# EFR32MG24B110F1536GM48 register map
Vendor: Silicon Labs; Series: EFR32; File version: B
Registers are 32-bit, read-write, reset 0x0 unless marked. A register's access mark holds for its fields unless they carry their own. Offsets are from the block's base; [hi:lo] are bit positions; {n}, {i} and the like mark numbered series.

## HFRCO0_NS — HFRCO0_NS Registers
Base 0x50010000
Same registers: HFRCO0_S 0x40010000, HFRCOEM23_S 0x4A000000, HFRCOEM23_NS 0x5A000000
0x00 IPVERSION ro reset 0x2
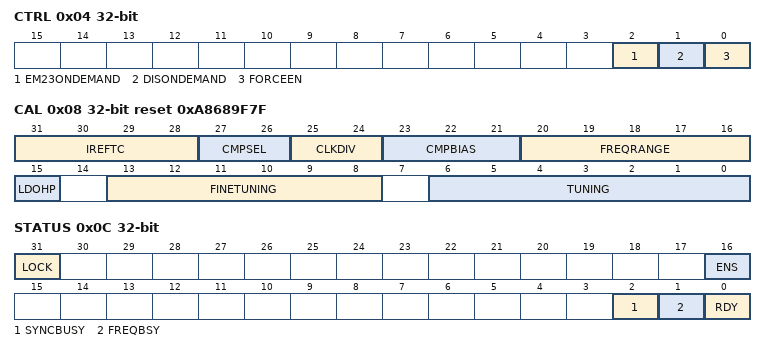
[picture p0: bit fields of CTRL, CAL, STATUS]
0x04 CTRL
  [2] EM23ONDEMAND
  [1] DISONDEMAND — Disable On-demand
  [0] FORCEEN — Force Enable
0x08 CAL reset 0xA8689F7F
  [31:28] IREFTC — Tempco Trim on Comparator Current
  [27:26] CMPSEL — Comparator Load Select
  [25:24] CLKDIV — Locally Divide HFRCO Clock Output
    0=DIV1 (Divide by 1.); 1=DIV2 (Divide by 2.); 2=DIV4 (Divide by 4.)
  [23:21] CMPBIAS — Comparator Bias Current
  [20:16] FREQRANGE — Frequency Range
  [15] LDOHP — LDO High Power Mode
  [13:8] FINETUNING — Fine Tuning Value
  [6:0] TUNING — Tuning Value
0x0C STATUS ro
  [31] LOCK — Lock Status
    0=UNLOCKED (HFRCO is unlocked); 1=LOCKED (HFRCO is locked)
  [16] ENS — Enable Status
  [2] SYNCBUSY — Synchronization Busy
  [1] FREQBSY — Frequency Updating Busy
  [0] RDY — Ready
0x10 IF
  [0] RDY — Ready Interrupt Flag
0x14 IEN
  [0] RDY — RDY Interrupt Enable
0x1C LOCK wo reset 0x8195
  [15:0] LOCKKEY
    0x8195=UNLOCK (Unlock code)

## HOSTMAILBOX_NS — HOSTMAILBOX_NS Registers
Base 0x50098000
Same registers: HOSTMAILBOX_S 0x40098000
{0x0+4i} MSGPTR{i} (i=0..3)
  [31:0] PTR — Pointer
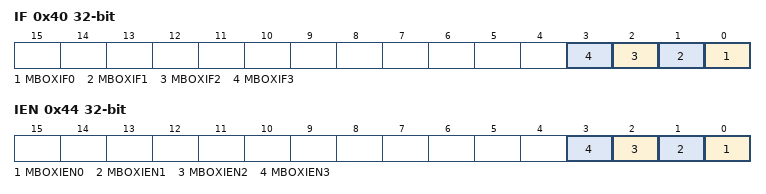
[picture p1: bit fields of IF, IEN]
0x40 IF
  [n] MBOXIF{n} (n=0..3) — Mailbox Interupt Flag
0x44 IEN
  [n] MBOXIEN{n} (n=0..3) — Mailbox Interrupt Enable

## ICACHE0_NS — ICACHE0_NS Registers
Base 0x50034000
Same registers: ICACHE0_S 0x40034000
0x00 IPVERSION ro — The read only IPVERSION field gives the version for this module. There may be minor software changes required for modules with different values of IPVERSION.
  [31:0] IPVERSION — IP version ID
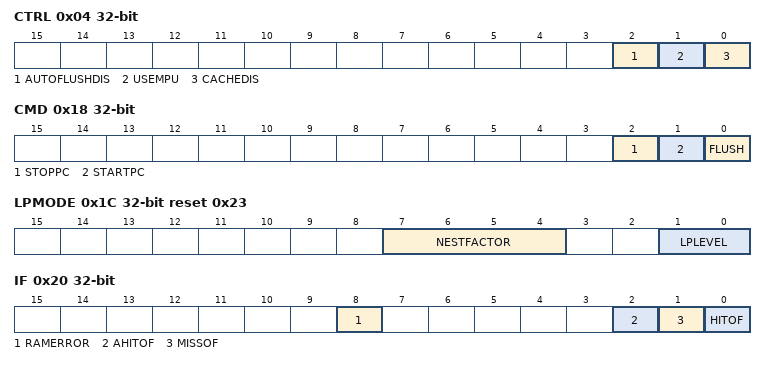
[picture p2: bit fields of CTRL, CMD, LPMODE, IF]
0x04 CTRL
  [2] AUTOFLUSHDIS — Automatic Flushing Disable
  [1] USEMPU
  [0] CACHEDIS — Cache Disable
0x08 PCHITS ro
  [31:0] PCHITS — Performance Counter Hits
0x0C PCMISSES ro
  [31:0] PCMISSES — Performance Counter Misses
0x10 PCAHITS ro
  [31:0] PCAHITS — Performance Counter Advanced Hits
0x14 STATUS ro
  [0] PCRUNNING
0x18 CMD wo
  [2] STOPPC — Stop Performance Counters
  [1] STARTPC — Start Performance Counters
  [0] FLUSH
0x1C LPMODE reset 0x23
  [7:4] NESTFACTOR — Low Power Nest Factor
  [1:0] LPLEVEL — Low Power Level
    0=BASIC (Base instruction cache functionality); 1=ADVANCED (Advanced buffering mode, where the cache uses the fetch pattern to predict highly accessed data and store it in low-energy memory); 3=MINACTIVITY (Minimum activity mode, which allows the cache to minimize activity in logic that it predicts has a low probability being used. This mode can introduce wait-states into the instruction fetch stream when the cache exits one of its low-activity states. The number of wait-states introduced is small, but users running with 0-wait-state memory and wishing to reduce the variability that the cache might introduce with additional wait-states may wish to lower the cache low-power level. Note, this mode includes the advanced buffering mode functionality.)
0x20 IF
  [8] RAMERROR — RAM error Interrupt Flag
  [2] AHITOF — Advanced Hit Overflow Interrupt Flag
  [1] MISSOF — Miss Overflow Interrupt Flag
  [0] HITOF — Hit Overflow Interrupt Flag
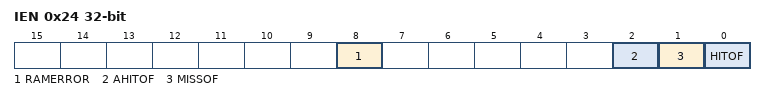
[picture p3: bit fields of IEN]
0x24 IEN
  [8] RAMERROR — RAM error Interrupt Enable
  [2] AHITOF — Advanced Hit Overflow Interrupt Enable
  [1] MISSOF — Miss Overflow Interrupt Enable
  [0] HITOF — Hit Overflow Interrupt Enable

## KEYSCAN_NS — KEYSCAN_NS Registers
Base 0x500B0000
Same registers: KEYSCAN_S 0x400B0000
0x00 IPVERSION ro reset 0x1
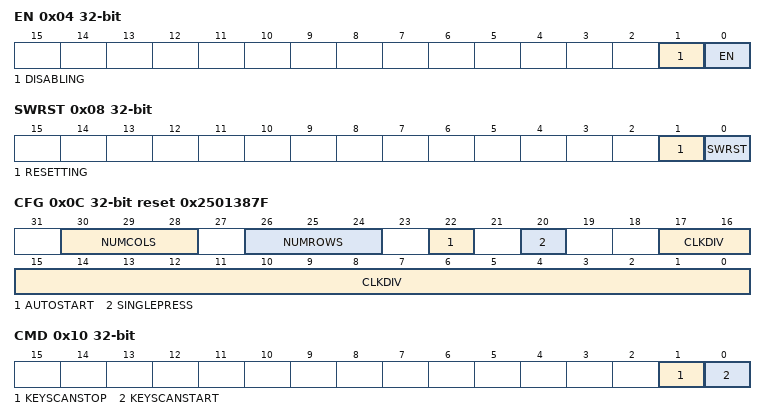
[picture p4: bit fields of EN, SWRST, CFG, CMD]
0x04 EN — Enable
  [1] DISABLING ro — Disablement busy status
  [0] EN — Enable
    0=DISABLE (Stops clocking and resets peripheral core logic.); 1=ENABLE (Enables clocking, and begins scanning if CFG.AUTOSTART is 0x1.)
0x08 SWRST — Software Reset
  [1] RESETTING ro — Software reset busy status
  [0] SWRST wo — Software reset command
0x0C CFG reset 0x2501387F — Config
  [30:28] NUMCOLS — Number of Columns
  [26:24] NUMROWS — Number of Rows
    0=RSV1 (1 Row is not supported; defaults to 3 instead); 1=RSV2 (2 Rows are not supported; defaults to 3 instead); {v}=ROW{v+1} ({v+1} Rows) (v=2..5)
  [22] AUTOSTART — Automatically Start
    0=AUTOSTARTDIS (Auto start is disabled); 1=AUTOSTARTEN (Auto start is enabled)
  [20] SINGLEPRESS
    0=MULTIPRESS (After KEYIF is set and then cleared, scanning will continue. This can give multiple interrupts for the same key press, but allow multiple key presses to be detected. To use this mode for multi-key detection, the ISR should update a section of memory of COLNUM bytes on each interrupt, until key release is detected. After key release, the section of memory where key presses are recorded can be processed.); 1=SINGLEPRESS (After KEYIF has been set and cleared, it will not set again until no key press is detected. This allows faster response since the ISR can start processing data as soon as the KEYIF is set.)
  [17:0] CLKDIV — Clock Divider
0x10 CMD wo — Command
  [1] KEYSCANSTOP, [0] KEYSCANSTART
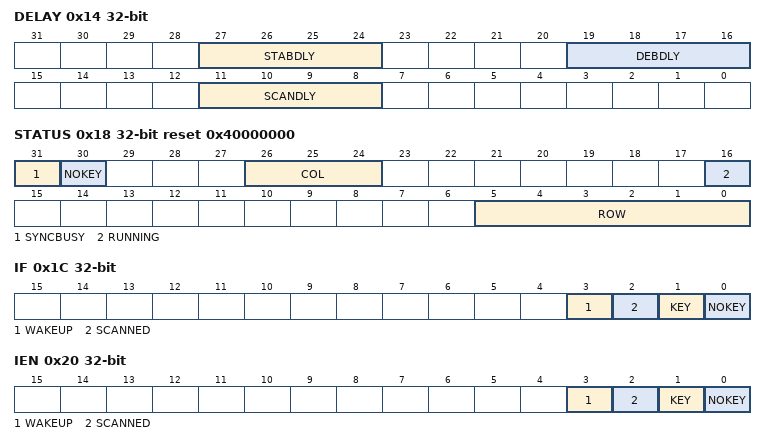
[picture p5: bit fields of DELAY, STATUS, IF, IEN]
0x14 DELAY
  [27:24] STABDLY — Row stable Delay
    0=2ms Row Stable Delay; 1=4ms Row Stable Delay; 2=6ms Row Stable Delay; 3=8ms Row Stable Delay; 4=10ms Row Stable Delay; 5=12ms Row Stable Delay; 6=14ms Row Stable Delay; 7=16ms Row Stable Delay; 8=18ms Row Stable Delay; 9=20ms Row Stable Delay; 10=22ms Row Stable Delay; 11=24ms Row Stable Delay; 12=26ms Row Stable Delay; 13=28ms Row Stable Delay; 14=30ms Row Stable Delay; 15=32ms Row Stable Delay
  [19:16] DEBDLY — Debounce Delay
    0=2ms Debounce Delay; 1=4ms Debounce Delay; 2=6ms Debounce Delay; 3=8ms Debounce Delay; 4=10ms Debounce Delay; 5=12ms Debounce Delay; 6=14ms Debounce Delay; 7=16ms Debounce Delay; 8=18ms Debounce Delay; 9=20ms Debounce Delay; 10=22ms Debounce Delay; 11=24ms Debounce Delay; 12=26ms Debounce Delay; 13=28ms Debounce Delay; 14=30ms Debounce Delay; 15=32ms Debounce Delay
  [11:8] SCANDLY — Scan Delay
    0=2ms Scan Delay; 1=4ms Scan Delay; 2=6ms Scan Delay; 3=8ms Scan Delay; 4=10ms Scan Delay; 5=12ms Scan Delay; 6=14ms Scan Delay; 7=16ms Scan Delay; 8=18ms Scan Delay; 9=20ms Scan Delay; 10=22ms Scan Delay; 11=24ms Scan Delay; 12=26ms Scan Delay; 13=28ms Scan Delay; 14=30ms Scan Delay; 15=32ms Scan Delay
0x18 STATUS ro reset 0x40000000
  [31] SYNCBUSY
  [30] NOKEY — No Key pressed status
  [26:24] COL — Column Latched
  [16] RUNNING
  [5:0] ROW — Row detection
0x1C IF — Interrupt Flags
  [3] WAKEUP
  [2] SCANNED — Completed scan
  [1] KEY — A key was pressed
  [0] NOKEY — No key was pressed
0x20 IEN — Interrupt Enables
  [3] WAKEUP
  [2] SCANNED — Completed Scanning
  [1] KEY — A Key was pressed
  [0] NOKEY — No Key was pressed
